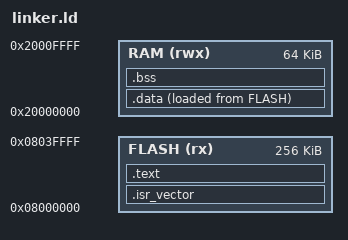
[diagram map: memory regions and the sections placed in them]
/* Matches Renode's bundled stm32f4_discovery platform: flash at
 * 0x08000000, sram at 0x20000000. Only using a small slice of each --
 * this is a two-task demo, not real firmware. */
MEMORY
{
    FLASH (rx)  : ORIGIN = 0x08000000, LENGTH = 256K
    RAM   (rwx) : ORIGIN = 0x20000000, LENGTH = 64K
}

SECTIONS
{
    .isr_vector :
    {
        KEEP(*(.isr_vector))
    } > FLASH

    .text :
    {
        *(.text*)
        *(.rodata*)
    } > FLASH

    _sidata = LOADADDR(.data);

    .data :
    {
        _sdata = .;
        *(.data*)
        _edata = .;
    } > RAM AT> FLASH

    .bss :
    {
        _sbss = .;
        *(.bss*)
        *(COMMON)
        _ebss = .;
    } > RAM

    . = ALIGN(8);
    _estack = ORIGIN(RAM) + LENGTH(RAM);
}
